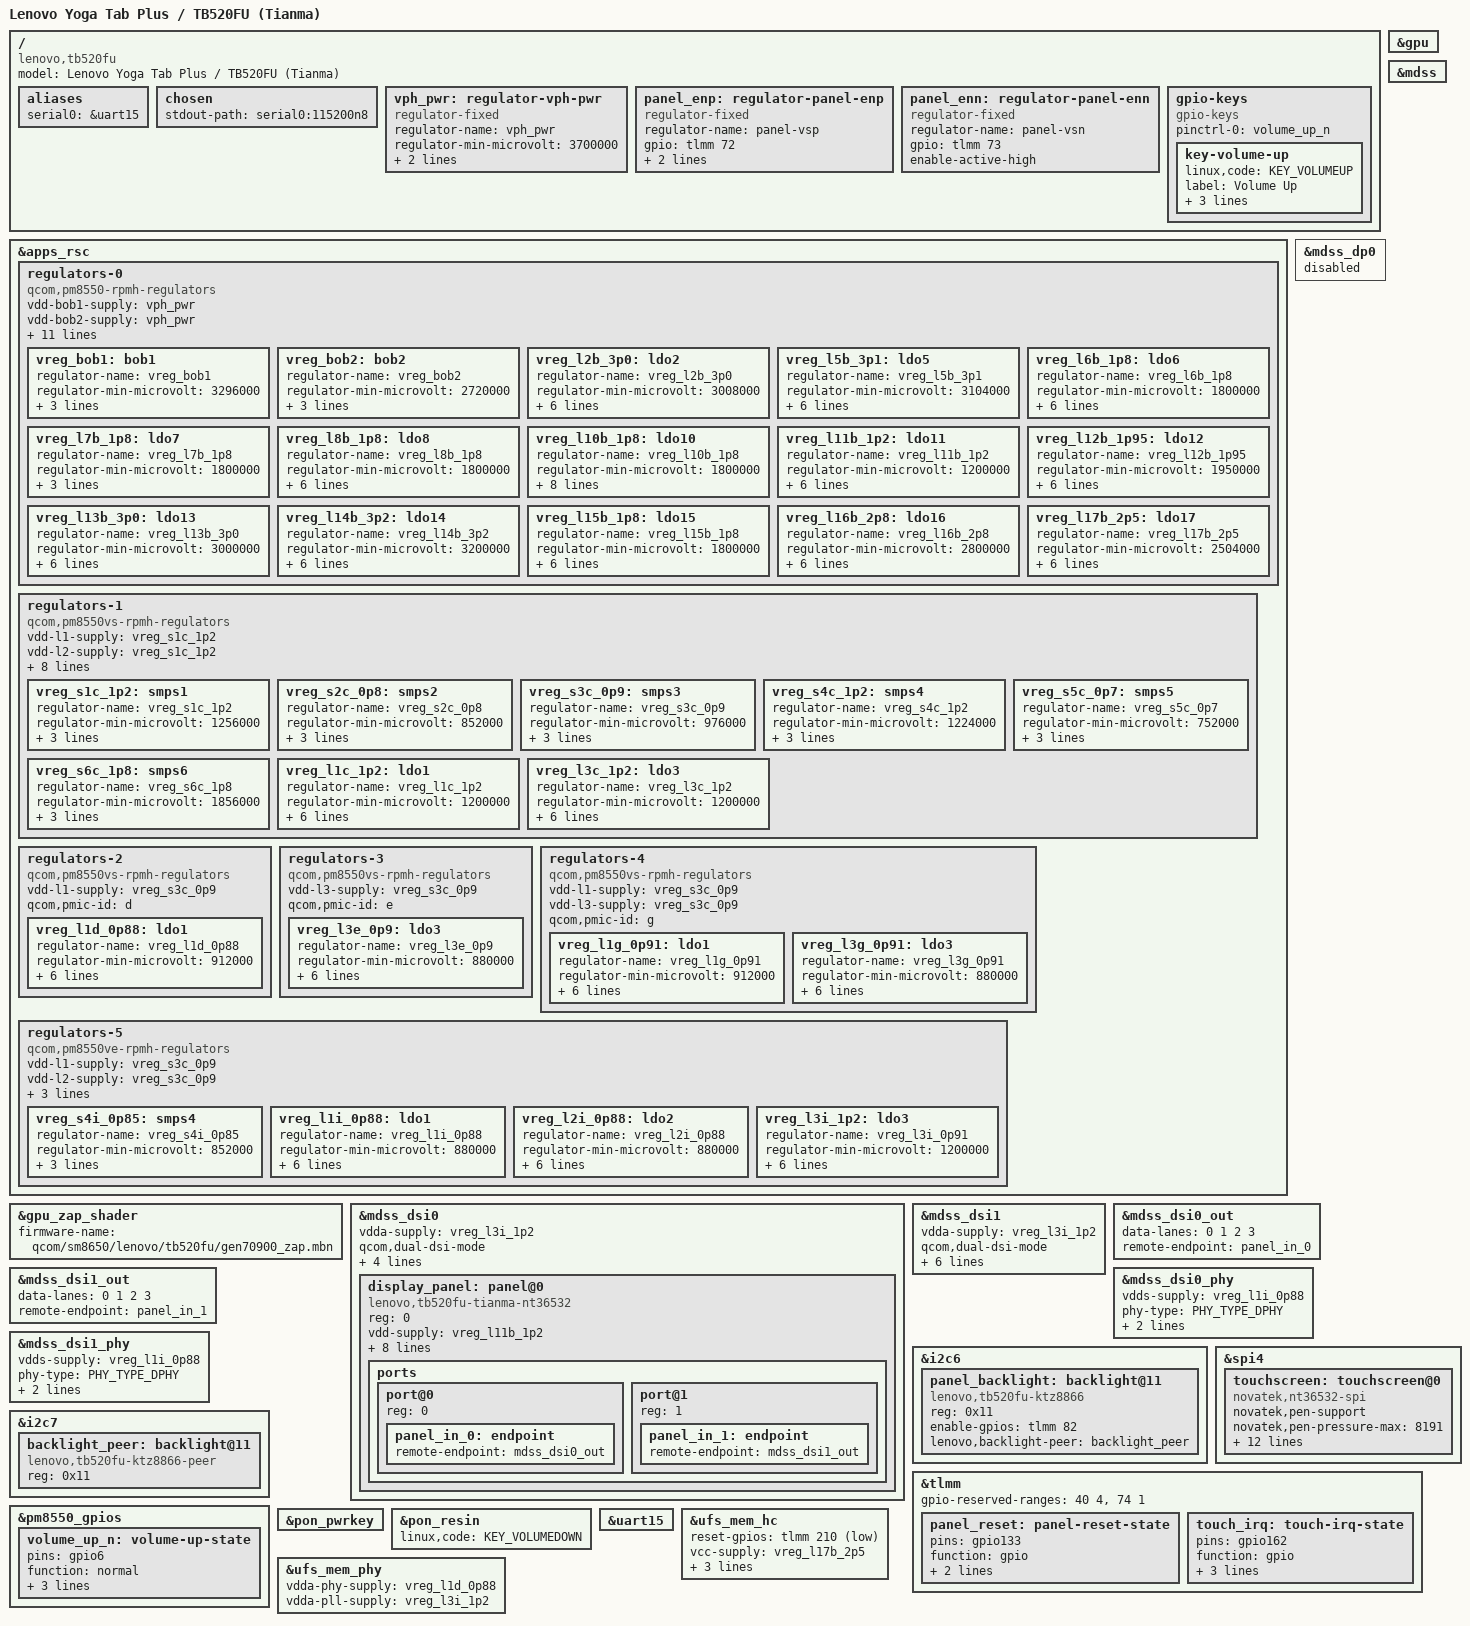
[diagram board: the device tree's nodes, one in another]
// SPDX-License-Identifier: BSD-3-Clause
/* Lenovo Yoga Tab Plus (TB520FU / lapis). Stock running.dts, not TB321FU wiring. */
#include <dt-bindings/input/input.h>
#include <dt-bindings/gpio/gpio.h>
#include <dt-bindings/interrupt-controller/irq.h>
#include <dt-bindings/regulator/qcom,rpmh-regulator.h>
#include <dt-bindings/phy/phy.h>
#include "sm8650.dtsi"
#include "pm8550.dtsi"
#include "pm8550b.dtsi"
#define PMK8550VE_SID 8
#include "pm8550ve.dtsi"
#include "pm8550vs.dtsi"
#include "pmk8550.dtsi"

/delete-node/ &rmtfs_mem;
/delete-node/ &hwfence_shbuf;
/delete-node/ &remoteproc_mpss;
/delete-node/ &qlink_logging_mem;
/delete-node/ &mpss_dsm_mem;
/delete-node/ &mpss_dsm_mem_2;
/delete-node/ &mpss_mem;
/delete-node/ &q6_mpss_dtb_mem;

/ {
	model = "Lenovo Yoga Tab Plus / TB520FU (Tianma)";
	compatible = "lenovo,tb520fu", "qcom,sm8650";
	aliases { serial0 = &uart15; };
	chosen { stdout-path = "serial0:115200n8"; };
	vph_pwr: regulator-vph-pwr {
		compatible = "regulator-fixed";
		regulator-name = "vph_pwr";
		regulator-min-microvolt = <3700000>;
		regulator-max-microvolt = <3700000>;
		regulator-always-on;
	};
	/* Bias is configured by the primary KTZ8866; GPIOs sequence the rails. */
	panel_enp: regulator-panel-enp {
		compatible = "regulator-fixed";
		regulator-name = "panel-vsp";
		gpio = <&tlmm 72 GPIO_ACTIVE_HIGH>;
		enable-active-high;
		startup-delay-us = <5000>;
	};
	panel_enn: regulator-panel-enn {
		compatible = "regulator-fixed";
		regulator-name = "panel-vsn";
		gpio = <&tlmm 73 GPIO_ACTIVE_HIGH>;
		enable-active-high;
	};
	gpio-keys {
		compatible = "gpio-keys";
		pinctrl-names = "default";
		pinctrl-0 = <&volume_up_n>;
		key-volume-up {
			linux,code = <KEY_VOLUMEUP>;
			label = "Volume Up";
			gpios = <&pm8550_gpios 6 GPIO_ACTIVE_LOW>;
			debounce-interval = <15>;
			wakeup-source;
		};
	};
};

&apps_rsc {
	regulators-0 {
		compatible = "qcom,pm8550-rpmh-regulators";

		vdd-bob1-supply = <&vph_pwr>;
		vdd-bob2-supply = <&vph_pwr>;
		vdd-l1-l4-l10-supply = <&vreg_s6c_1p8>;
		vdd-l2-l13-l14-supply = <&vreg_bob1>;
		vdd-l3-supply = <&vreg_s1c_1p2>;
		vdd-l5-l16-supply = <&vreg_bob1>;
		vdd-l6-l7-supply = <&vreg_bob1>;
		vdd-l8-l9-supply = <&vreg_bob1>;
		vdd-l11-supply = <&vreg_s1c_1p2>;
		vdd-l12-supply = <&vreg_s6c_1p8>;
		vdd-l15-supply = <&vreg_s6c_1p8>;
		vdd-l17-supply = <&vreg_bob2>;

		qcom,pmic-id = "b";

		vreg_bob1: bob1 {
			regulator-name = "vreg_bob1";
			regulator-min-microvolt = <3296000>;
			regulator-max-microvolt = <3960000>;
			regulator-initial-mode = <RPMH_REGULATOR_MODE_HPM>;
		};

		vreg_bob2: bob2 {
			regulator-name = "vreg_bob2";
			regulator-min-microvolt = <2720000>;
			regulator-max-microvolt = <3008000>;
			regulator-initial-mode = <RPMH_REGULATOR_MODE_HPM>;
		};

		vreg_l2b_3p0: ldo2 {
			regulator-name = "vreg_l2b_3p0";
			regulator-min-microvolt = <3008000>;
			regulator-max-microvolt = <3008000>;
			regulator-initial-mode = <RPMH_REGULATOR_MODE_HPM>;
			regulator-allow-set-load;
			regulator-allowed-modes = <RPMH_REGULATOR_MODE_LPM
						   RPMH_REGULATOR_MODE_HPM>;
		};

		vreg_l5b_3p1: ldo5 {
			regulator-name = "vreg_l5b_3p1";
			regulator-min-microvolt = <3104000>;
			regulator-max-microvolt = <3104000>;
			regulator-initial-mode = <RPMH_REGULATOR_MODE_HPM>;
			regulator-allow-set-load;
			regulator-allowed-modes = <RPMH_REGULATOR_MODE_LPM
						   RPMH_REGULATOR_MODE_HPM>;
		};

		vreg_l6b_1p8: ldo6 {
			regulator-name = "vreg_l6b_1p8";
			regulator-min-microvolt = <1800000>;
			regulator-max-microvolt = <3008000>;
			regulator-initial-mode = <RPMH_REGULATOR_MODE_HPM>;
			regulator-allow-set-load;
			regulator-allowed-modes = <RPMH_REGULATOR_MODE_LPM
						   RPMH_REGULATOR_MODE_HPM>;
		};

		vreg_l7b_1p8: ldo7 {
			regulator-name = "vreg_l7b_1p8";
			regulator-min-microvolt = <1800000>;
			regulator-max-microvolt = <3008000>;
			regulator-initial-mode = <RPMH_REGULATOR_MODE_HPM>;
		};

		vreg_l8b_1p8: ldo8 {
			regulator-name = "vreg_l8b_1p8";
			regulator-min-microvolt = <1800000>;
			regulator-max-microvolt = <3008000>;
			regulator-initial-mode = <RPMH_REGULATOR_MODE_HPM>;
			regulator-allow-set-load;
			regulator-allowed-modes = <RPMH_REGULATOR_MODE_LPM
						   RPMH_REGULATOR_MODE_HPM>;
		};

		vreg_l10b_1p8: ldo10 {
			regulator-name = "vreg_l10b_1p8";
			regulator-min-microvolt = <1800000>;
			regulator-max-microvolt = <1800000>;
			regulator-initial-mode = <RPMH_REGULATOR_MODE_HPM>;
			regulator-allow-set-load;
			regulator-boot-on;
			regulator-always-on;
			regulator-allowed-modes = <RPMH_REGULATOR_MODE_LPM
						   RPMH_REGULATOR_MODE_HPM>;
		};

		vreg_l11b_1p2: ldo11 {
			regulator-name = "vreg_l11b_1p2";
			regulator-min-microvolt = <1200000>;
			regulator-max-microvolt = <1504000>;
			regulator-initial-mode = <RPMH_REGULATOR_MODE_HPM>;
			regulator-allow-set-load;
			regulator-allowed-modes = <RPMH_REGULATOR_MODE_LPM
						   RPMH_REGULATOR_MODE_HPM>;
		};

		vreg_l12b_1p95: ldo12 {
			regulator-name = "vreg_l12b_1p95";
			regulator-min-microvolt = <1950000>;
			regulator-max-microvolt = <1950000>;
			regulator-initial-mode = <RPMH_REGULATOR_MODE_HPM>;
			regulator-allow-set-load;
			regulator-allowed-modes = <RPMH_REGULATOR_MODE_LPM
						   RPMH_REGULATOR_MODE_HPM>;
		};

		vreg_l13b_3p0: ldo13 {
			regulator-name = "vreg_l13b_3p0";
			regulator-min-microvolt = <3000000>;
			regulator-max-microvolt = <3000000>;
			regulator-initial-mode = <RPMH_REGULATOR_MODE_HPM>;
			regulator-allow-set-load;
			regulator-allowed-modes = <RPMH_REGULATOR_MODE_LPM
						   RPMH_REGULATOR_MODE_HPM>;
		};

		vreg_l14b_3p2: ldo14 {
			regulator-name = "vreg_l14b_3p2";
			regulator-min-microvolt = <3200000>;
			regulator-max-microvolt = <3200000>;
			regulator-initial-mode = <RPMH_REGULATOR_MODE_HPM>;
			regulator-allow-set-load;
			regulator-allowed-modes = <RPMH_REGULATOR_MODE_LPM
						   RPMH_REGULATOR_MODE_HPM>;
		};

		vreg_l15b_1p8: ldo15 {
			regulator-name = "vreg_l15b_1p8";
			regulator-min-microvolt = <1800000>;
			regulator-max-microvolt = <1800000>;
			regulator-initial-mode = <RPMH_REGULATOR_MODE_HPM>;
			regulator-allow-set-load;
			regulator-allowed-modes = <RPMH_REGULATOR_MODE_LPM
						   RPMH_REGULATOR_MODE_HPM>;
		};

		vreg_l16b_2p8: ldo16 {
			regulator-name = "vreg_l16b_2p8";
			regulator-min-microvolt = <2800000>;
			regulator-max-microvolt = <2800000>;
			regulator-initial-mode = <RPMH_REGULATOR_MODE_HPM>;
			regulator-allow-set-load;
			regulator-allowed-modes = <RPMH_REGULATOR_MODE_LPM
						   RPMH_REGULATOR_MODE_HPM>;
		};

		vreg_l17b_2p5: ldo17 {
			regulator-name = "vreg_l17b_2p5";
			regulator-min-microvolt = <2504000>;
			regulator-max-microvolt = <2504000>;
			regulator-initial-mode = <RPMH_REGULATOR_MODE_HPM>;
			regulator-allow-set-load;
			regulator-allowed-modes = <RPMH_REGULATOR_MODE_LPM
						   RPMH_REGULATOR_MODE_HPM>;
		};
	};

	regulators-1 {
		compatible = "qcom,pm8550vs-rpmh-regulators";

		vdd-l1-supply = <&vreg_s1c_1p2>;
		vdd-l2-supply = <&vreg_s1c_1p2>;
		vdd-l3-supply = <&vreg_s1c_1p2>;
		vdd-s1-supply = <&vph_pwr>;
		vdd-s2-supply = <&vph_pwr>;
		vdd-s3-supply = <&vph_pwr>;
		vdd-s4-supply = <&vph_pwr>;
		vdd-s5-supply = <&vph_pwr>;
		vdd-s6-supply = <&vph_pwr>;

		qcom,pmic-id = "c";

		vreg_s1c_1p2: smps1 {
			regulator-name = "vreg_s1c_1p2";
			regulator-min-microvolt = <1256000>;
			regulator-max-microvolt = <1348000>;
			regulator-initial-mode = <RPMH_REGULATOR_MODE_HPM>;
		};

		vreg_s2c_0p8: smps2 {
			regulator-name = "vreg_s2c_0p8";
			regulator-min-microvolt = <852000>;
			regulator-max-microvolt = <1036000>;
			regulator-initial-mode = <RPMH_REGULATOR_MODE_HPM>;
		};

		vreg_s3c_0p9: smps3 {
			regulator-name = "vreg_s3c_0p9";
			regulator-min-microvolt = <976000>;
			regulator-max-microvolt = <1064000>;
			regulator-initial-mode = <RPMH_REGULATOR_MODE_HPM>;
		};

		vreg_s4c_1p2: smps4 {
			regulator-name = "vreg_s4c_1p2";
			regulator-min-microvolt = <1224000>;
			regulator-max-microvolt = <1280000>;
			regulator-initial-mode = <RPMH_REGULATOR_MODE_HPM>;
		};

		vreg_s5c_0p7: smps5 {
			regulator-name = "vreg_s5c_0p7";
			regulator-min-microvolt = <752000>;
			regulator-max-microvolt = <900000>;
			regulator-initial-mode = <RPMH_REGULATOR_MODE_HPM>;
		};

		vreg_s6c_1p8: smps6 {
			regulator-name = "vreg_s6c_1p8";
			regulator-min-microvolt = <1856000>;
			regulator-max-microvolt = <2000000>;
			regulator-initial-mode = <RPMH_REGULATOR_MODE_HPM>;
		};

		vreg_l1c_1p2: ldo1 {
			regulator-name = "vreg_l1c_1p2";
			regulator-min-microvolt = <1200000>;
			regulator-max-microvolt = <1200000>;
			regulator-initial-mode = <RPMH_REGULATOR_MODE_HPM>;
			regulator-allow-set-load;
			regulator-allowed-modes = <RPMH_REGULATOR_MODE_LPM
						   RPMH_REGULATOR_MODE_HPM>;
		};

		vreg_l3c_1p2: ldo3 {
			regulator-name = "vreg_l3c_1p2";
			regulator-min-microvolt = <1200000>;
			regulator-max-microvolt = <1200000>;
			regulator-initial-mode = <RPMH_REGULATOR_MODE_HPM>;
			regulator-allow-set-load;
			regulator-allowed-modes = <RPMH_REGULATOR_MODE_LPM
						   RPMH_REGULATOR_MODE_HPM>;
		};
	};

	regulators-2 {
		compatible = "qcom,pm8550vs-rpmh-regulators";

		vdd-l1-supply = <&vreg_s3c_0p9>;

		qcom,pmic-id = "d";

		vreg_l1d_0p88: ldo1 {
			regulator-name = "vreg_l1d_0p88";
			regulator-min-microvolt = <912000>;
			regulator-max-microvolt = <920000>;
			regulator-initial-mode = <RPMH_REGULATOR_MODE_HPM>;
			regulator-allow-set-load;
			regulator-allowed-modes = <RPMH_REGULATOR_MODE_LPM
						   RPMH_REGULATOR_MODE_HPM>;
		};
	};

	regulators-3 {
		compatible = "qcom,pm8550vs-rpmh-regulators";

		vdd-l3-supply = <&vreg_s3c_0p9>;

		qcom,pmic-id = "e";

		vreg_l3e_0p9: ldo3 {
			regulator-name = "vreg_l3e_0p9";
			regulator-min-microvolt = <880000>;
			regulator-max-microvolt = <920000>;
			regulator-initial-mode = <RPMH_REGULATOR_MODE_HPM>;
			regulator-allow-set-load;
			regulator-allowed-modes = <RPMH_REGULATOR_MODE_LPM
						   RPMH_REGULATOR_MODE_HPM>;
		};
	};

	regulators-4 {
		compatible = "qcom,pm8550vs-rpmh-regulators";

		vdd-l1-supply = <&vreg_s3c_0p9>;
		vdd-l3-supply = <&vreg_s3c_0p9>;

		qcom,pmic-id = "g";

		vreg_l1g_0p91: ldo1 {
			regulator-name = "vreg_l1g_0p91";
			regulator-min-microvolt = <912000>;
			regulator-max-microvolt = <920000>;
			regulator-initial-mode = <RPMH_REGULATOR_MODE_HPM>;
			regulator-allow-set-load;
			regulator-allowed-modes = <RPMH_REGULATOR_MODE_LPM
						   RPMH_REGULATOR_MODE_HPM>;
		};

		vreg_l3g_0p91: ldo3 {
			regulator-name = "vreg_l3g_0p91";
			regulator-min-microvolt = <880000>;
			regulator-max-microvolt = <912000>;
			regulator-initial-mode = <RPMH_REGULATOR_MODE_HPM>;
			regulator-allow-set-load;
			regulator-allowed-modes = <RPMH_REGULATOR_MODE_LPM
						   RPMH_REGULATOR_MODE_HPM>;
		};
	};

	regulators-5 {
		compatible = "qcom,pm8550ve-rpmh-regulators";

		vdd-l1-supply = <&vreg_s3c_0p9>;
		vdd-l2-supply = <&vreg_s3c_0p9>;
		vdd-l3-supply = <&vreg_s1c_1p2>;
		vdd-s4-supply = <&vph_pwr>;

		qcom,pmic-id = "i";

		vreg_s4i_0p85: smps4 {
			regulator-name = "vreg_s4i_0p85";
			regulator-min-microvolt = <852000>;
			regulator-max-microvolt = <1004000>;
			regulator-initial-mode = <RPMH_REGULATOR_MODE_HPM>;
		};

		vreg_l1i_0p88: ldo1 {
			regulator-name = "vreg_l1i_0p88";
			regulator-min-microvolt = <880000>;
			regulator-max-microvolt = <912000>;
			regulator-initial-mode = <RPMH_REGULATOR_MODE_HPM>;
			regulator-allow-set-load;
			regulator-allowed-modes = <RPMH_REGULATOR_MODE_LPM
						   RPMH_REGULATOR_MODE_HPM>;
		};

		vreg_l2i_0p88: ldo2 {
			regulator-name = "vreg_l2i_0p88";
			regulator-min-microvolt = <880000>;
			regulator-max-microvolt = <912000>;
			regulator-initial-mode = <RPMH_REGULATOR_MODE_HPM>;
			regulator-allow-set-load;
			regulator-allowed-modes = <RPMH_REGULATOR_MODE_LPM
						   RPMH_REGULATOR_MODE_HPM>;
		};

		vreg_l3i_1p2: ldo3 {
			regulator-name = "vreg_l3i_0p91";
			regulator-min-microvolt = <1200000>;
			regulator-max-microvolt = <1200000>;
			regulator-initial-mode = <RPMH_REGULATOR_MODE_HPM>;
			regulator-allow-set-load;
			regulator-allowed-modes = <RPMH_REGULATOR_MODE_LPM
						   RPMH_REGULATOR_MODE_HPM>;
		};
	};
};

&gpu { status = "okay"; };
&gpu_zap_shader { firmware-name = "qcom/sm8650/lenovo/tb520fu/gen70900_zap.mbn"; };
&mdss { status = "okay"; };
&mdss_dp0 { status = "disabled"; };
&mdss_dsi0 {
	vdda-supply = <&vreg_l3i_1p2>;
	qcom,dual-dsi-mode;
	qcom,sync-dual-dsi;
	qcom,master-dsi;
	qcom,dsc-slices-per-packet = <2>;
	qcom,dsc-scr-version = <1>;
	status = "okay";
	display_panel: panel@0 {
		compatible = "lenovo,tb520fu-tianma-nt36532";
		reg = <0>;
		vdd-supply = <&vreg_l11b_1p2>;
		vddio-supply = <&vreg_l12b_1p95>;
		avdd-supply = <&vreg_l13b_3p0>;
		enp-supply = <&panel_enp>;
		enn-supply = <&panel_enn>;
		reset-gpios = <&tlmm 133 GPIO_ACTIVE_LOW>;
		pinctrl-names = "default";
		pinctrl-0 = <&panel_reset>;
		backlight = <&panel_backlight>;
		rotation = <0>;
		ports {
			#address-cells = <1>;
			#size-cells = <0>;
			port@0 { reg = <0>; panel_in_0: endpoint { remote-endpoint = <&mdss_dsi0_out>; }; };
			port@1 { reg = <1>; panel_in_1: endpoint { remote-endpoint = <&mdss_dsi1_out>; }; };
		};
	};
};
&mdss_dsi1 {
	vdda-supply = <&vreg_l3i_1p2>;
	qcom,dual-dsi-mode;
	qcom,sync-dual-dsi;
	qcom,dsc-slices-per-packet = <2>;
	qcom,dsc-scr-version = <1>;
	assigned-clock-parents = <&mdss_dsi0_phy DSI_BYTE_PLL_CLK>, <&mdss_dsi0_phy DSI_PIXEL_PLL_CLK>;
	status = "okay";
};
&mdss_dsi0_out { data-lanes = <0 1 2 3>; remote-endpoint = <&panel_in_0>; };
&mdss_dsi1_out { data-lanes = <0 1 2 3>; remote-endpoint = <&panel_in_1>; };
&mdss_dsi0_phy {
	vdds-supply = <&vreg_l1i_0p88>;
	phy-type = <PHY_TYPE_DPHY>;
	qcom,mdss-dsi-panel-phy-timings = [00 25 0a 0a 1b 18 0a 0a 0a 02 04 00 1f 0f];
	status = "okay";
};
&mdss_dsi1_phy {
	vdds-supply = <&vreg_l1i_0p88>;
	phy-type = <PHY_TYPE_DPHY>;
	qcom,mdss-dsi-panel-phy-timings = [00 25 0a 0a 1b 18 0a 0a 0a 02 04 00 1f 0f];
	status = "okay";
};
&i2c6 {
	status = "okay";
	panel_backlight: backlight@11 {
		compatible = "lenovo,tb520fu-ktz8866";
		reg = <0x11>;
		enable-gpios = <&tlmm 82 GPIO_ACTIVE_HIGH>;
		lenovo,backlight-peer = <&backlight_peer>;
	};
};
&i2c7 {
	status = "okay";
	backlight_peer: backlight@11 {
		compatible = "lenovo,tb520fu-ktz8866-peer";
		reg = <0x11>;
	};
};
&spi4 {
	status = "okay";
	touchscreen: touchscreen@0 {
		compatible = "novatek,nt36532-spi";
		novatek,pen-support;
		novatek,pen-pressure-max = <8191>;
		reg = <0>;
		spi-max-frequency = <9600000>;
		interrupt-parent = <&tlmm>;
		interrupts = <162 IRQ_TYPE_EDGE_RISING>;
		pinctrl-names = "default";
		pinctrl-0 = <&touch_irq>;
		/* The vendor disables HW reset; do not drive GPIO161 speculatively. */
		touchscreen-size-x = <18401>;
		touchscreen-size-y = <29441>;
		touchscreen-swapped-x-y;
		touchscreen-inverted-x;
		firmware-name = "qcom/sm8650/lenovo/tb520fu/novatek_ts_tianma_fw.bin";
		panel = <&display_panel>;
	};
};
&tlmm {
	/* Stock secure pins: GPIO40..43 and GPIO74. */
	gpio-reserved-ranges = <40 4>, <74 1>;
	panel_reset: panel-reset-state {
		pins = "gpio133";
		function = "gpio";
		drive-strength = <8>;
		bias-disable;
	};
	touch_irq: touch-irq-state {
		pins = "gpio162";
		function = "gpio";
		drive-strength = <2>;
		bias-pull-up;
		input-enable;
	};
};
&pm8550_gpios {
	volume_up_n: volume-up-state {
		pins = "gpio6";
		function = "normal";
		power-source = <1>;
		bias-pull-up;
		input-enable;
	};
};
&pon_pwrkey { status = "okay"; };
&pon_resin { linux,code = <KEY_VOLUMEDOWN>; status = "okay"; };
&uart15 { status = "okay"; };
&ufs_mem_hc {
	reset-gpios = <&tlmm 210 GPIO_ACTIVE_LOW>;

	vcc-supply = <&vreg_l17b_2p5>;
	vcc-max-microamp = <1300000>;
	vccq-supply = <&vreg_l1c_1p2>;
	vccq-max-microamp = <1200000>;

	status = "okay";
};

&ufs_mem_phy {
	vdda-phy-supply = <&vreg_l1d_0p88>;
	vdda-pll-supply = <&vreg_l3i_1p2>;

	status = "okay";
};
#include "sm8650-lenovo-tb520fu-peripherals.dtsi"
